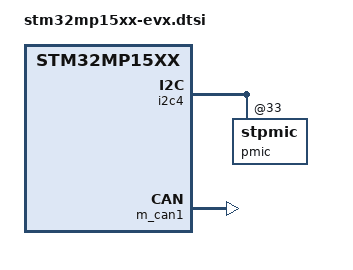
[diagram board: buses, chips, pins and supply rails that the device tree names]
// SPDX-License-Identifier: (GPL-2.0+ OR BSD-3-Clause)
/*
 * Copyright (C) STMicroelectronics 2017 - All Rights Reserved
 * Author: Ludovic Barre <ludovic.barre@st.com> for STMicroelectronics.
 */

#include <dt-bindings/input/input.h>
#include <dt-bindings/soc/stm32-hdp.h>

&i2c4 {
	pmic: stpmic@33 {
		regulators {
			v1v8: ldo6 {
				regulator-enable-ramp-delay = <300000>;
			};
		};
	};
};

&m_can1 {
	pinctrl-names = "default", "sleep";
	pinctrl-0 = <&m_can1_pins_a>;
	pinctrl-1 = <&m_can1_sleep_pins_a>;
	status = "okay";
};

&sdmmc3 {
	pinctrl-names = "default", "opendrain", "sleep";
	pinctrl-0 = <&sdmmc3_b4_pins_a>;
	pinctrl-1 = <&sdmmc3_b4_od_pins_a>;
	pinctrl-2 = <&sdmmc3_b4_sleep_pins_a>;
	broken-cd;
	st,neg-edge;
	bus-width = <4>;
	vmmc-supply = <&v3v3>;
	status = "disabled";
};
